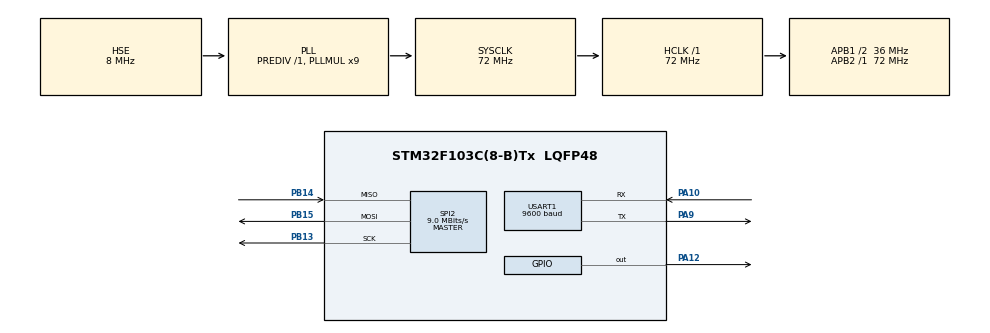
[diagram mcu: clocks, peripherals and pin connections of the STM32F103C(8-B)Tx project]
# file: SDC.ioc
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FATFS._MAX_SS=4096
FATFS._USE_LFN=1
Mcu.Family=STM32F1
Mcu.Name=STM32F103C(8-B)Tx
Mcu.Package=LQFP48
NVIC.PriorityGroup=NVIC_PRIORITYGROUP_4
PA10.Mode=Asynchronous
PA10.Signal=USART1_RX
PA12.Signal=GPIO_Output
PA13.Mode=Serial_Wire
PA13.Signal=SYS_JTMS-SWDIO
PA14.Mode=Serial_Wire
PA14.Signal=SYS_JTCK-SWCLK
PA9.Mode=Asynchronous
PA9.Signal=USART1_TX
PB13.Mode=Full_Duplex_Master
PB13.Signal=SPI2_SCK
PB14.Mode=Full_Duplex_Master
PB14.Signal=SPI2_MISO
PB15.Mode=Full_Duplex_Master
PB15.Signal=SPI2_MOSI
PD0-OSC_IN.Mode=HSE-External-Oscillator
PD0-OSC_IN.Signal=RCC_OSC_IN
PD1-OSC_OUT.Mode=HSE-External-Oscillator
PD1-OSC_OUT.Signal=RCC_OSC_OUT
ProjectManager.HeapSize=0x200
ProjectManager.StackSize=0x400
ProjectManager.TargetToolchain=MDK-ARM V5
RCC.AHBFreq_Value=72000000
RCC.APB1CLKDivider=RCC_HCLK_DIV2
RCC.APB1Freq_Value=36000000
RCC.APB1TimFreq_Value=72000000
RCC.APB2Freq_Value=72000000
RCC.APB2TimFreq_Value=72000000
RCC.HCLKFreq_Value=72000000
RCC.PLLMUL=RCC_PLL_MUL9
RCC.PLLSourceVirtual=RCC_PLLSOURCE_HSE
RCC.SYSCLKFreq_VALUE=72000000
RCC.SYSCLKSource=RCC_SYSCLKSOURCE_PLLCLK
RCC.USBFreq_Value=72000000
SPI2.BaudRatePrescaler=SPI_BAUDRATEPRESCALER_4
SPI2.CalculateBaudRate=9.0 MBits/s
SPI2.Direction=SPI_DIRECTION_2LINES
SPI2.Mode=SPI_MODE_MASTER
SPI2.VirtualType=VM_MASTER
USART1.BaudRate=9600
USART1.VirtualMode=VM_ASYNC
VP_FATFS_VS_Generic.Mode=User_defined
board=custom

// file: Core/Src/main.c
/* USER CODE BEGIN Header */
/**
  ******************************************************************************
  * @file           : main.c
  * @brief          : Main program body
  ******************************************************************************
  * @attention
  *
  * <h2><center>&copy; Copyright (c) 2022 STMicroelectronics.
  * All rights reserved.</center></h2>
  *
  * This software component is licensed by ST under Ultimate Liberty license
  * SLA0044, the "License"; You may not use this file except in compliance with
  * the License. You may obtain a copy of the License at:
  *                             www.st.com/SLA0044
  *
  ******************************************************************************
  */
/* USER CODE END Header */
#include "main.h"
#include "fatfs.h"
#include <string.h>

SPI_HandleTypeDef hspi2;

UART_HandleTypeDef huart1;

/* USER CODE BEGIN PV */
FATFS fs;
FATFS *pfs;
FIL fil;
FRESULT fres;
DWORD fre_clust;
uint32_t total, free1;
char buffer[100];

/* USER CODE END PV */

void SystemClock_Config(void);
static void MX_GPIO_Init(void);
static void MX_SPI2_Init(void);
static void MX_USART1_UART_Init(void);
/* USER CODE BEGIN PFP */
/* to send the data to uart */
void send_uart (char *string)
{
	uint8_t len = strlen (string);
	HAL_UART_Transmit(&huart1, (uint8_t *) string, len, 2000);   // transmit in blocking mode
}

/* USER CODE END PFP */

int main(void)
{

  /* MCU Configuration--------------------------------------------------------*/

  /* Reset of all peripherals, Initializes the Flash interface and the Systick. */
  HAL_Init();

  /* Configure the system clock */
  SystemClock_Config();

  /* Initialize all configured peripherals */
  MX_GPIO_Init();
  MX_SPI2_Init();
  MX_FATFS_Init();
  MX_USART1_UART_Init();
  /* USER CODE BEGIN 2 */
// Kiem tra gui uart
// send_uart("hello\n");

/**************** Code mau 1 *********************/
//	  HAL_GPIO_WritePin(GPIOA,GPIO_PIN_12,GPIO_PIN_SET);
//    HAL_Delay(10);
//	 /* Mount SD Card */
//  if(f_mount(&fs, "", 0) != FR_OK)
//    _Error_Handler(__FILE__, __LINE__);
//
//	 /* Check free space */
//  if(f_getfree("", &fre_clust, &pfs) != FR_OK)
//    _Error_Handler(__FILE__, __LINE__);
//
//  total = (uint32_t)((pfs->n_fatent - 2) * pfs->csize * 0.5);
//  free1 = (uint32_t)(fre_clust * pfs->csize * 0.5);
//
//  /* Free space is less than 1kb */
//  if(free1 < 1)
//    _Error_Handler(__FILE__, __LINE__);
//
//	 /* Open file to read */
//  if(f_open(&fil, "file chuyen bay.txt", FA_READ) != FR_OK)
//    _Error_Handler(__FILE__, __LINE__);
//
//  while(f_gets(buffer, sizeof(buffer), &fil))
//  {
//   HAL_Delay(500);
//	 send_uart(buffer);
//  }
//
//  /* Close file */
//  if(f_close(&fil) != FR_OK)
//    _Error_Handler(__FILE__, __LINE__);
//
//  /* Unmount SDCARD */
//  if(f_mount(NULL, "", 1) != FR_OK)
//    _Error_Handler(__FILE__, __LINE__);

/************* Code mau 2 ******************/
//		f_open(&fil, "file chuyen bay.txt", FA_READ);
//  // Reads line by line until the end
//  while(f_gets(buffer, sizeof(buffer), &fil))
//  {
//    // Can use the buffer for something useful
//   HAL_Delay(500);
//	 send_uart(buffer);
//  }
//  f_close(&fil);

  /* USER CODE END 2 */

  /* Infinite loop */
  while (1)
  {

  }
}

void SystemClock_Config(void)
{
  RCC_OscInitTypeDef RCC_OscInitStruct = {0};
  RCC_ClkInitTypeDef RCC_ClkInitStruct = {0};

  /** Initializes the RCC Oscillators according to the specified parameters
  * in the RCC_OscInitTypeDef structure.
  */
  RCC_OscInitStruct.OscillatorType = RCC_OSCILLATORTYPE_HSE;
  RCC_OscInitStruct.HSEState = RCC_HSE_ON;
  RCC_OscInitStruct.HSEPredivValue = RCC_HSE_PREDIV_DIV1;
  RCC_OscInitStruct.HSIState = RCC_HSI_ON;
  RCC_OscInitStruct.PLL.PLLState = RCC_PLL_ON;
  RCC_OscInitStruct.PLL.PLLSource = RCC_PLLSOURCE_HSE;
  RCC_OscInitStruct.PLL.PLLMUL = RCC_PLL_MUL9;
  if (HAL_RCC_OscConfig(&RCC_OscInitStruct) != HAL_OK)
  {
    Error_Handler();
  }
  /** Initializes the CPU, AHB and APB buses clocks
  */
  RCC_ClkInitStruct.ClockType = RCC_CLOCKTYPE_HCLK|RCC_CLOCKTYPE_SYSCLK
                              |RCC_CLOCKTYPE_PCLK1|RCC_CLOCKTYPE_PCLK2;
  RCC_ClkInitStruct.SYSCLKSource = RCC_SYSCLKSOURCE_PLLCLK;
  RCC_ClkInitStruct.AHBCLKDivider = RCC_SYSCLK_DIV1;
  RCC_ClkInitStruct.APB1CLKDivider = RCC_HCLK_DIV2;
  RCC_ClkInitStruct.APB2CLKDivider = RCC_HCLK_DIV1;

  if (HAL_RCC_ClockConfig(&RCC_ClkInitStruct, FLASH_LATENCY_2) != HAL_OK)
  {
    Error_Handler();
  }
}

static void MX_SPI2_Init(void)
{

  /* SPI2 parameter configuration*/
  hspi2.Instance = SPI2;
  hspi2.Init.Mode = SPI_MODE_MASTER;
  hspi2.Init.Direction = SPI_DIRECTION_2LINES;
  hspi2.Init.DataSize = SPI_DATASIZE_8BIT;
  hspi2.Init.CLKPolarity = SPI_POLARITY_LOW;
  hspi2.Init.CLKPhase = SPI_PHASE_1EDGE;
  hspi2.Init.NSS = SPI_NSS_SOFT;
  hspi2.Init.BaudRatePrescaler = SPI_BAUDRATEPRESCALER_4;
  hspi2.Init.FirstBit = SPI_FIRSTBIT_MSB;
  hspi2.Init.TIMode = SPI_TIMODE_DISABLE;
  hspi2.Init.CRCCalculation = SPI_CRCCALCULATION_DISABLE;
  hspi2.Init.CRCPolynomial = 10;
  if (HAL_SPI_Init(&hspi2) != HAL_OK)
  {
    Error_Handler();
  }

}

static void MX_USART1_UART_Init(void)
{

  huart1.Instance = USART1;
  huart1.Init.BaudRate = 9600;
  huart1.Init.WordLength = UART_WORDLENGTH_8B;
  huart1.Init.StopBits = UART_STOPBITS_1;
  huart1.Init.Parity = UART_PARITY_NONE;
  huart1.Init.Mode = UART_MODE_TX_RX;
  huart1.Init.HwFlowCtl = UART_HWCONTROL_NONE;
  huart1.Init.OverSampling = UART_OVERSAMPLING_16;
  if (HAL_UART_Init(&huart1) != HAL_OK)
  {
    Error_Handler();
  }

}

static void MX_GPIO_Init(void)
{
  GPIO_InitTypeDef GPIO_InitStruct = {0};

  /* GPIO Ports Clock Enable */
  __HAL_RCC_GPIOD_CLK_ENABLE();
  __HAL_RCC_GPIOB_CLK_ENABLE();
  __HAL_RCC_GPIOA_CLK_ENABLE();

  /*Configure GPIO pin Output Level */
  HAL_GPIO_WritePin(GPIOA, GPIO_PIN_12, GPIO_PIN_RESET);

  /*Configure GPIO pin : PA12 */
  GPIO_InitStruct.Pin = GPIO_PIN_12;
  GPIO_InitStruct.Mode = GPIO_MODE_OUTPUT_PP;
  GPIO_InitStruct.Pull = GPIO_NOPULL;
  GPIO_InitStruct.Speed = GPIO_SPEED_FREQ_LOW;
  HAL_GPIO_Init(GPIOA, &GPIO_InitStruct);

}

void Error_Handler(void)
{
}

/************************ (C) COPYRIGHT STMicroelectronics *****END OF FILE****/
